# AT32F423 register map
Vendor: Keil; Series: AT32F423; File version: 1.0
CPU: CM4 r0p1, little endian, no MPU, FPU, 4 interrupt priority bits
Registers are 32-bit, read-write, reset 0x0 unless marked. A register's access mark holds for its fields unless they carry their own. Offsets are from the block's base; [hi:lo] are bit positions; 'fields as' and 'values as' point back to an identical list.

## DEBUG — Debug support
Base 0xE0042000
0x00 IDCODE ro — DEBUG IDCODE
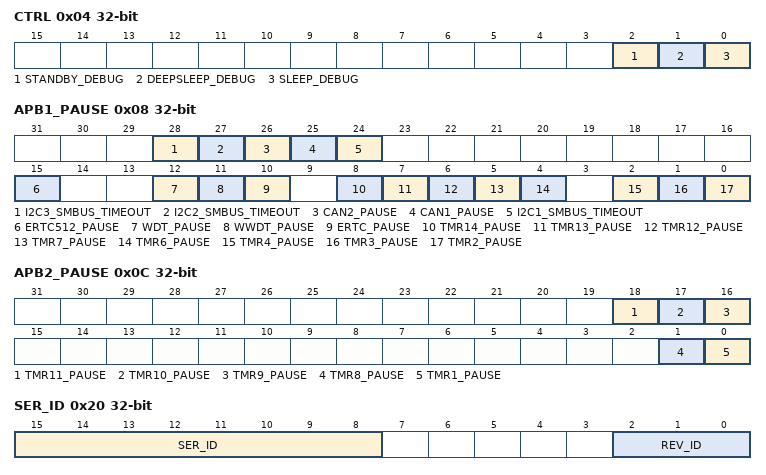
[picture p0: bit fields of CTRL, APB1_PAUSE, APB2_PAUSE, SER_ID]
0x04 CTRL — DEBUG CTRL
  [2] STANDBY_DEBUG — Debug Standby mode control bit
    on read: 0=Disabled (The whole 1.2V digital circuit is unpowered in Standby mode); 1=Enabled (The whole 1.2V digital circuit is not unpowered in Standby mode, and the system clock is provided by the internal RC oscillator (HICK)) | on write: 0=Disable (The whole 1.2V digital circuit is unpowered in Standby mode); 1=Enable (The whole 1.2V digital circuit is not unpowered in Standby mode, and the system clock is provided by the internal RC oscillator (HICK))
  [1] DEEPSLEEP_DEBUG — Debug Deepsleep mode control bit
    on read: 0=Disabled (In Deepsleep mode, all clocks in the 1.2V domain are disabled); 1=Enabled (In Deepsleep mode, system clock is provided by the internal RC oscillator (HICK)) | on write: 0=Disable (In Deepsleep mode, all clocks in the 1.2V domain are disabled); 1=Enable (In Deepsleep mode, system clock is provided by the internal RC oscillator (HICK))
  [0] SLEEP_DEBUG — Debug Sleep mode control bit
    on read: 0=Disabled (When entering Sleep mode, CPU HCLK clock is disabled, but other clocks remain active); 1=Enabled (When entering Sleep mode, all clocks keep running) | on write: 0=Disable (When entering Sleep mode, CPU HCLK clock is disabled, but other clocks remain active); 1=Enable (When entering Sleep mode, all clocks keep running)
0x08 APB1_PAUSE — DEBUG APB1 PAUSE
  [28] I2C3_SMBUS_TIMEOUT
    0=Run (I2C SMBUS timeout control works normally); 1=Stop (I2C SMBUS timeout control stops running)
  [27] I2C2_SMBUS_TIMEOUT
    values as I2C3_SMBUS_TIMEOUT
  [26] CAN2_PAUSE
    0=Run (Running normally); 1=Stopped running
  [25] CAN1_PAUSE
    0=Run (Running normally); 1=Stopped running
  [24] I2C1_SMBUS_TIMEOUT
    values as I2C3_SMBUS_TIMEOUT
  [15] ERTC512_PAUSE
    0=Run (Running normally); 1=Stopped running
  [12] WDT_PAUSE
    0=Run (Running normally); 1=Stopped running
  [11] WWDT_PAUSE
    0=Run (Running normally); 1=Stopped running
  [10] ERTC_PAUSE
    0=Run (Running normally); 1=Stopped running
  [8] TMR14_PAUSE
    0=Run (Running normally); 1=Stopped running
  [7] TMR13_PAUSE
    0=Run (Running normally); 1=Stopped running
  [6] TMR12_PAUSE
    0=Run (Running normally); 1=Stopped running
  [5] TMR7_PAUSE
    0=Run (Running normally); 1=Stopped running
  [4] TMR6_PAUSE
    0=Run (Running normally); 1=Stopped running
  [2] TMR4_PAUSE
    0=Run (Running normally); 1=Stopped running
  [1] TMR3_PAUSE
    0=Run (Running normally); 1=Stopped running
  [0] TMR2_PAUSE
    0=Run (Running normally); 1=Stopped running
0x0C APB2_PAUSE — DEBUG APB2 PAUSE
  [all] fields
    0=Run (Running normally); 1=Stopped running
  [18] TMR11_PAUSE
  [17] TMR10_PAUSE
  [16] TMR9_PAUSE
  [1] TMR8_PAUSE
  [0] TMR1_PAUSE
0x20 SER_ID ro — SERIES ID
  [15:8] SER_ID — series ID
  [2:0] REV_ID — version ID
    0=A (Revision A)

## CRC — CRC calculation unit
Base 0x40023000
0x00 DT reset 0xFFFFFFFF — Data register
0x04 CDT — Common data register
  [7:0] CDT — Common Data
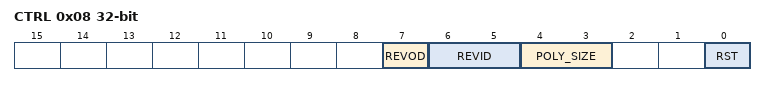
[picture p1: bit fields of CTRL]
0x08 CTRL — Control register
  [7] REVOD — Reverse output data
    0=NoEffect; 1=WordReverse
  [6:5] REVID — Reverse input data
    0=NoEffect; 1=ByteReverse; 2=HalfWordReverse; 3=WordReverse
  [4:3] POLY_SIZE — Polynomial size
    0=bits32 (32 bits); 1=bits16 (16 bits); 2=bits8 (8 bits); 3=bits7 (7 bits)
  [0] RST write-1-sets — Reset bit
    on write: 1=Reset CRC calculation unit, the data register is set as 0xFFFF FFFF
0x10 IDT reset 0xFFFFFFFF — Initial data register
0x14 POLY reset 0x4C11DB7 — Polynomial coefficient register
